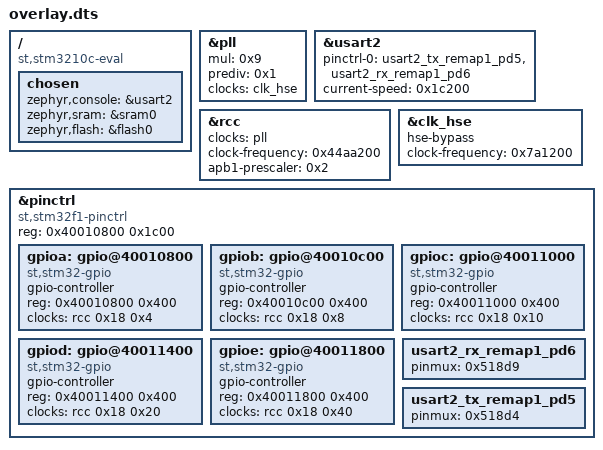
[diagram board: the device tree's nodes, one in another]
/ {
	compatible = "st,stm3210c-eval";
	chosen {
		zephyr,console = &usart2;
		zephyr,sram = &sram0;
		zephyr,flash = &flash0;
	};
};
&pll{
	status = "okay";
	mul = < 0x9 >;
	prediv = < 0x1 >;
	clocks = < &clk_hse >;
};
&usart2{
	status = "okay";
	pinctrl-0 = < &usart2_tx_remap1_pd5 &usart2_rx_remap1_pd6 >;
	pinctrl-names = "default";
	current-speed = < 0x1c200 >;
};
&rcc{
	clocks = < &pll >;
	clock-frequency = < 0x44aa200 >;
	apb1-prescaler = < 0x2 >;
};
&clk_hse{
	status = "okay";
	hse-bypass;
	clock-frequency = < 0x7a1200 >;
};
&pinctrl{
	compatible = "st,stm32f1-pinctrl";
	#address-cells = < 0x1 >;
	#size-cells = < 0x1 >;
	reg = < 0x40010800 0x1c00 >;
	gpioa: gpio@40010800 {
		compatible = "st,stm32-gpio";
		gpio-controller;
		#gpio-cells = < 0x2 >;
		reg = < 0x40010800 0x400 >;
		clocks = < &rcc 0x18 0x4 >;
	};
	gpiob: gpio@40010c00 {
		compatible = "st,stm32-gpio";
		gpio-controller;
		#gpio-cells = < 0x2 >;
		reg = < 0x40010c00 0x400 >;
		clocks = < &rcc 0x18 0x8 >;
	};
	gpioc: gpio@40011000 {
		compatible = "st,stm32-gpio";
		gpio-controller;
		#gpio-cells = < 0x2 >;
		reg = < 0x40011000 0x400 >;
		clocks = < &rcc 0x18 0x10 >;
	};
	gpiod: gpio@40011400 {
		compatible = "st,stm32-gpio";
		gpio-controller;
		#gpio-cells = < 0x2 >;
		reg = < 0x40011400 0x400 >;
		clocks = < &rcc 0x18 0x20 >;
	};
	gpioe: gpio@40011800 {
		compatible = "st,stm32-gpio";
		gpio-controller;
		#gpio-cells = < 0x2 >;
		reg = < 0x40011800 0x400 >;
		clocks = < &rcc 0x18 0x40 >;
	};
	usart2_rx_remap1_pd6: usart2_rx_remap1_pd6 {
		pinmux = < 0x518d9 >;
	};
	usart2_tx_remap1_pd5: usart2_tx_remap1_pd5 {
		pinmux = < 0x518d4 >;
	};
};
